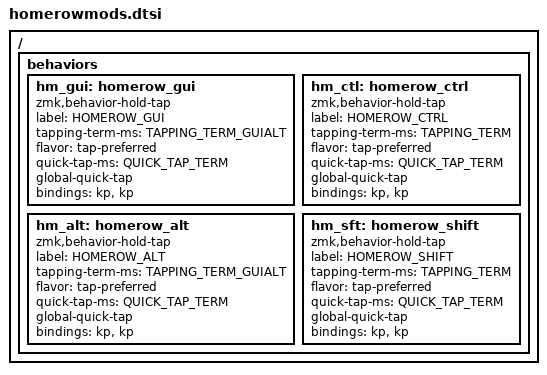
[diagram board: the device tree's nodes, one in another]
#include "homerowmods.h"

/ {
    behaviors {
        hm_gui: homerow_gui {
            compatible = "zmk,behavior-hold-tap";
            label = "HOMEROW_GUI";
            #binding-cells = <2>;
            tapping-term-ms = <TAPPING_TERM_GUIALT>;
            flavor = "tap-preferred";
			quick-tap-ms = <QUICK_TAP_TERM>;
            global-quick-tap;
            bindings = <&kp>, <&kp>;
        };

        hm_alt: homerow_alt {
            compatible = "zmk,behavior-hold-tap";
            label = "HOMEROW_ALT";
            #binding-cells = <2>;
            tapping-term-ms = <TAPPING_TERM_GUIALT>;
            flavor = "tap-preferred";
			quick-tap-ms = <QUICK_TAP_TERM>;
            global-quick-tap;
            bindings = <&kp>, <&kp>;
        };

        hm_ctl: homerow_ctrl {
            compatible = "zmk,behavior-hold-tap";
            label = "HOMEROW_CTRL";
            #binding-cells = <2>;
            tapping-term-ms = <TAPPING_TERM>;
			flavor = "tap-preferred";
			quick-tap-ms = <QUICK_TAP_TERM>;
            global-quick-tap;
            bindings = <&kp>, <&kp>;
        };

        hm_sft: homerow_shift {
            compatible = "zmk,behavior-hold-tap";
            label = "HOMEROW_SHIFT";
            #binding-cells = <2>;
            tapping-term-ms = <TAPPING_TERM>;
            flavor = "tap-preferred";
			quick-tap-ms = <QUICK_TAP_TERM>;
            global-quick-tap;
            bindings = <&kp>, <&kp>;
        };
    };
};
